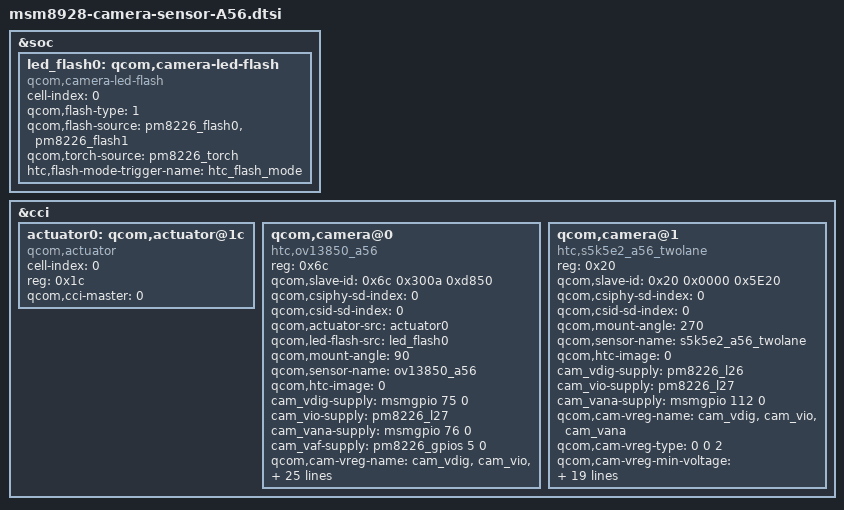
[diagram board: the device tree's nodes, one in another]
/*
 * Copyright (c) 2013, The Linux Foundation. All rights reserved.
 *
 * This program is free software; you can redistribute it and/or modify
 * it under the terms of the GNU General Public License version 2 and
 * only version 2 as published by the Free Software Foundation.
 *
 * This program is distributed in the hope that it will be useful,
 * but WITHOUT ANY WARRANTY; without even the implied warranty of
 * MERCHANTABILITY or FITNESS FOR A PARTICULAR PURPOSE.  See the
 * GNU General Public License for more details.
 */

&soc {
	led_flash0: qcom,camera-led-flash {
		cell-index = <0>;
		compatible = "qcom,camera-led-flash";
		qcom,flash-type = <1>;
		qcom,flash-source = <&pm8226_flash0 &pm8226_flash1>;
		qcom,torch-source = <&pm8226_torch>;
                htc,flash-mode-trigger-name = "htc_flash_mode";
	};
};

&cci {
	actuator0: qcom,actuator@1c {
		cell-index = <0>;
		reg = <0x1c>;
		compatible = "qcom,actuator";
		qcom,cci-master = <0>;
	};

	qcom,camera@0 {
		compatible = "htc,ov13850_a56";
		reg = <0x6c>;
		qcom,slave-id = <0x6c 0x300a 0xd850>;
		qcom,csiphy-sd-index = <0>;
		qcom,csid-sd-index = <0>;
		qcom,actuator-src = <&actuator0>;
		qcom,led-flash-src = <&led_flash0>;
		qcom,mount-angle = <90>;
		qcom,sensor-name = "ov13850_a56";
		qcom,htc-image = <0>;
		cam_vdig-supply = <&msmgpio 75 0>;
		cam_vio-supply = <&pm8226_l27>;
		cam_vana-supply = <&msmgpio 76 0>;
		cam_vaf-supply = <&pm8226_gpios 5 0>;
		qcom,cam-vreg-name = "cam_vdig", "cam_vio", "cam_vana", "cam_vaf";
		qcom,cam-vreg-type = <2 0 2 2>;
		qcom,cam-vreg-min-voltage = <1200000 1800000 2850000 2850000>;
		qcom,cam-vreg-max-voltage = <1200000 1800000 2850000 2850000>;
		qcom,cam-vreg-op-mode = <0 0 0 0>;
		qcom,cam-vreg-gpios-index = <2 99 3 4>;
		qcom,gpio-no-mux = <0>;

		gpios = <&msmgpio 26 0>,
			<&msmgpio 36 0>,
			<&msmgpio 75 0>,
			<&msmgpio 76 0>,
			<&pm8226_gpios 5 0>,
			<&msmgpio 112 0>,
			<&msmgpio 34 0>;
		qcom,gpio-reset = <1>;
		qcom,gpio-standby = <5>;
		qcom,gpio-vcm-pwd = <6>;
		qcom,gpio-req-tbl-num = <0 1 2 3 4 5 6>;
		qcom,gpio-req-tbl-flags = <0 0 0 0 0 0 0>;
		qcom,gpio-req-tbl-label = "MCLK_CPU",
					  "CAM_PWDN",
					  "CAM_D1V2_EN",
					  "CAM_A2V85_EN",
					  "CAM_VCM_2V85_EN",
					  "CAM2_A2V85_EN",
					  "CAM_SEL";

		qcom,csi-lane-assign = <0x4320>;
		qcom,csi-lane-mask = <0x1F>;
		qcom,sensor-position = <0>;
		qcom,sensor-mode = <1>;
		qcom,cci-master = <0>;
		status = "ok";
	};
	qcom,camera@1 {
		compatible = "htc,s5k5e2_a56_twolane";
		reg = <0x20>;
		qcom,slave-id = <0x20 0x0000 0x5E20>;
		qcom,csiphy-sd-index = <0>;
		qcom,csid-sd-index = <0>;
		qcom,mount-angle = <270>;
		qcom,sensor-name = "s5k5e2_a56_twolane";
		qcom,htc-image = <0>;

		cam_vdig-supply = <&pm8226_l26>;
		cam_vio-supply = <&pm8226_l27>;
		cam_vana-supply = <&msmgpio 112 0>;
		qcom,cam-vreg-name = "cam_vdig", "cam_vio", "cam_vana";
		qcom,cam-vreg-type = <0 0 2>;
		qcom,cam-vreg-min-voltage = <1200000 1800000 2850000>;
		qcom,cam-vreg-max-voltage = <1200000 1800000 2850000>;
		qcom,cam-vreg-op-mode = <0 0 0>;
		qcom,cam-vreg-gpios-index = <99 99 2>;

		qcom,gpio-no-mux = <0>;
		gpios = <&msmgpio 27 0>,
			<&msmgpio 28 0>,
			<&msmgpio 112 0>,
			<&msmgpio 34 0>;

		qcom,gpio-reset = <1>;
		qcom,gpio-standby = <3>;
		qcom,gpio-req-tbl-num = <0 1 2 3>;
		qcom,gpio-req-tbl-flags = <0 0 0 0>;
		qcom,gpio-req-tbl-label = "MCLK2_CPU",
					  "CAM2_RESET",
					  "CAM2_A2V85_EN",
					  "CAM_SEL";
		qcom,csi-lane-assign = <0x4320>;
		qcom,csi-lane-mask = <0x7>;
		qcom,sensor-position = <1>;
		qcom,sensor-mode = <1>;
		qcom,cci-master = <0>;
		status = "ok";
	};
};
